# MSP430G2231 register map
Registers are 8-bit, read-write, reset 0x0 unless marked. A register's access mark holds for its fields unless they carry their own. Offsets are from the block's base; [hi:lo] are bit positions.

## SYSTEM_CLOCK
Base 0x00000052
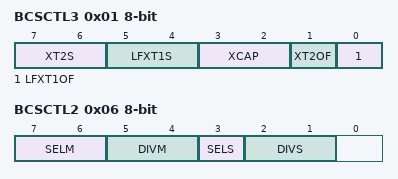
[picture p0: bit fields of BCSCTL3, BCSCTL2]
0x01 BCSCTL3 — Basic Clock System Control 3
  [7:6] XT2S — Mode 0 for XT2
    0=Mode 0 for XT2 : 0.4 - 1 MHz; 1=Mode 1 for XT2 : 1 - 4 MHz; 2=Mode 2 for XT2 : 2 - 16 MHz; 3=Mode 3 for XT2 : Digital input signal
  [5:4] LFXT1S — Mode 0 for LFXT1 (XTS = 0)
    0=Mode 0 for LFXT1 : Normal operation; 1=Mode 1 for LFXT1 : Reserved; 2=Mode 2 for LFXT1 : VLO; 3=Mode 3 for LFXT1 : Digital input signal
  [3:2] XCAP — XIN/XOUT Cap 0
    0=XIN/XOUT Cap : 0 pF; 1=XIN/XOUT Cap : 6 pF; 2=XIN/XOUT Cap : 10 pF; 3=XIN/XOUT Cap : 12.5 pF
  [1] XT2OF — High frequency oscillator 2 fault flag
  [0] LFXT1OF — Low/high Frequency Oscillator Fault Flag
0x04 DCOCTL — DCO Clock Frequency Control
  [7:5] DCO — DCO Select Bit 0
  [7:0] DCOCTL — DCO Clock Frequency Control register
  [4:0] MOD — Modulation Bit 0
0x05 BCSCTL1 — Basic Clock System Control 1
  [7] XT2OFF — Enable XT2CLK
  [6] XTS — LFXTCLK 0:Low Freq. / 1: High Freq.
  [5:4] DIVA — ACLK Divider 0
    0=ACLK Divider 0: /1; 1=ACLK Divider 1: /2; 2=ACLK Divider 2: /4; 3=ACLK Divider 3: /8
  [7:0] BCSCTL1 — Basic Clock System Control 1 register
  [3:0] RSEL — Range Select Bit 0
0x06 BCSCTL2 — Basic Clock System Control 2
  [7:6] SELM — MCLK Source Select 0
    0=MCLK Source Select 0: DCOCLK; 1=MCLK Source Select 1: DCOCLK; 2=MCLK Source Select 2: XT2CLK/LFXTCLK; 3=MCLK Source Select 3: LFXTCLK
  [5:4] DIVM — MCLK Divider 0
    0=MCLK Divider 0: /1; 1=MCLK Divider 1: /2; 2=MCLK Divider 2: /4; 3=MCLK Divider 3: /8
  [3] SELS — SMCLK Source Select 0:DCOCLK / 1:XT2CLK/LFXTCLK
  [2:1] DIVS — SMCLK Divider 0
    0=SMCLK Divider 0: /1; 1=SMCLK Divider 1: /2; 2=SMCLK Divider 2: /4; 3=SMCLK Divider 3: /8

## USI
Base 0x00000078
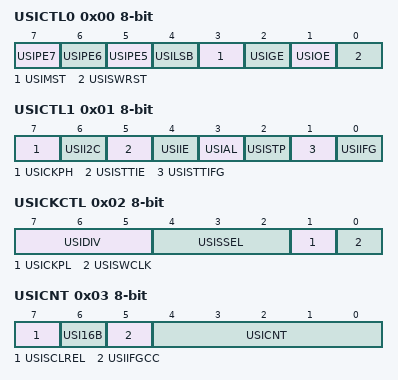
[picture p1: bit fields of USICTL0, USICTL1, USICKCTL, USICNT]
0x00 USICTL0 — USI Control Register 0
  [7] USIPE7 — USI Port Enable Px.7
  [6] USIPE6 — USI Port Enable Px.6
  [5] USIPE5 — USI Port Enable Px.5
  [4] USILSB — USI LSB first 1:LSB / 0:MSB
  [3] USIMST — USI Master Select 0:Slave / 1:Master
  [2] USIGE — USI General Output Enable Latch
  [1] USIOE — USI Output Enable
  [0] USISWRST — USI Software Reset
0x00 USISR 16-bit — USI Word Shift Register
  [15:0] USISR — Contents of the USI word shift register
0x01 USICTL1 — USI Control Register 1
  [7] USICKPH — USI Sync. Mode: Clock Phase
  [6] USII2C — USI I2C Mode
  [5] USISTTIE — USI START Condition interrupt enable
  [4] USIIE — USI Counter Interrupt enable
  [3] USIAL — USI Arbitration Lost
  [2] USISTP — USI STOP Condition received
  [1] USISTTIFG — USI START Condition interrupt Flag
  [0] USIIFG — USI Counter Interrupt Flag
0x02 USICKCTL — USI Clock Control Register
  [7:5] USIDIV — USI Clock Divider 2
    0=DIV_BY_1 (000b = Divide by 1); 1=DIV_BY_2 (001b = Divide by 2); 2=DIV_BY_4 (010b = Divide by 4); 3=DIV_BY_8 (011b = Divide by 8); 4=DIV_BY_16 (100b = Divide by 16); 5=DIV_BY_32 (101b = Divide by 32); 6=DIV_BY_64 (110b = Divide by 64); 7=DIV_BY_128 (111b = Divide by 128)
  [4:2] USISSEL — USI Clock Source Select 2
    0=SCLK (000b = SCLK (Not used in SPI mode)); 1=ACLK (001b = ACLK); 3=SMCLK (011b = SMCLK); 4=USISWCLK (100b = USISWCLK bit); 5=TA0CCR0 (101b = TA0CCR0); 6=TA0CCR1 (110b = TA0CCR1); 7=TA0CCR2 (111b = TA0CCR2 (Reserved on MSP430F20xx devices))
  [1] USICKPL — USI Clock Polarity 0:Inactive=Low / 1:Inactive=High
  [0] USISWCLK — USI Software Clock
0x03 USICNT — USI Bit Counter Register
  [7] USISCLREL — USI SCL Released
  [6] USI16B — USI 16 Bit Shift Register Enable
  [5] USIIFGCC — USI Interrupt Flag Clear Control
  [4:0] USICNT — USI bit count. The USICNT bits set the number of bits to be received or transmitted
0x04 USISRL — USI Low Byte Shift Register
  [7:0] USISRL — Contents of the USI low byte shift register
0x05 USISRH — USI High Byte Shift Register
  [7:0] USISRH — Contents of the USI high byte shift register
